# RA register map
Vendor: Renesas; Series: All Chips; File version: x.xx
Registers are 32-bit, read-write, reset 0x0 unless marked. A register's access mark holds for its fields unless they carry their own. Offsets are from the block's base; [hi:lo] are bit positions; {n}, {i} and the like mark numbered series.

## R_SPI0 — Serial Peripheral Interface
Base 0x40072000
Same registers: R_SPI1 0x40072100
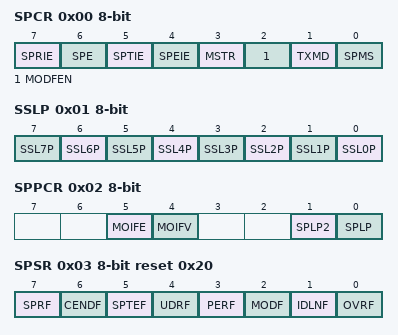
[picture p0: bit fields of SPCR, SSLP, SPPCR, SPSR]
0x00 SPCR 8-bit — SPI Control Register
  [7] SPRIE — SPI Receive Buffer Full Interrupt Enable
    0=Disables the generation of SPI receive buffer full interrupt requests; 1=Enables the generation of SPI receive buffer full interrupt requests
  [6] SPE — SPI Function Enable
    0=Disables the SPI function; 1=Enables the SPI function
  [5] SPTIE — Transmit Buffer Empty Interrupt Enable
    0=Disables the generation of transmit buffer empty interrupt requests; 1=Enables the generation of transmit buffer empty interrupt requests
  [4] SPEIE — SPI Error Interrupt Enable
    0=Disables the generation of SPI error interrupt requests; 1=Enables the generation of SPI error interrupt requests
  [3] MSTR — SPI Master/Slave Mode Select
    0=Slave mode; 1=Master mode
  [2] MODFEN — Mode Fault Error Detection Enable
    0=Disables the detection of mode fault error; 1=Enables the detection of mode fault error
  [1] TXMD — Communications Operating Mode Select
    0=Full-duplex synchronous serial communications; 1=Serial communications consisting of only transmit operations
  [0] SPMS — SPI Mode Select
    0=SPI operation (4-wire method); 1=Clock synchronous operation (3-wire method)
0x01 SSLP 8-bit — SPI Slave Select Polarity Register
  [n] SSL{n}P (n=0..7) — SSL{n} Signal Polarity Setting
    0=SSL{n} signal is active low; 1=SSL{n} signal is active high
0x02 SPPCR 8-bit — SPI Pin Control Register
  [5] MOIFE — MOSI Idle Value Fixing Enable
    0=MOSI output value equals final data from previous transfer; 1=MOSI output value equals the value set in the MOIFV bit
  [4] MOIFV — MOSI Idle Fixed Value
    0=The level output on the MOSIn pin during MOSI idling corresponds to low; 1=The level output on the MOSIn pin during MOSI idling corresponds to high
  [1] SPLP2 — SPI Loopback 2
    0=Normal mode; 1=Loopback mode (data is not inverted for transmission)
  [0] SPLP — SPI Loopback
    0=Normal mode; 1=Loopback mode (data is inverted for transmission)
0x03 SPSR 8-bit reset 0x20 — SPI Status Register
  [7] SPRF write-0-clears read-modifies — SPI Receive Buffer Full Flag
    0=No valid data in SPDR; 1=Valid data found in SPDR
  [6] CENDF — Communication End Flag
    0=The RSPI is not communicating or communicating; 1=The RSPI communication completed
  [5] SPTEF write-0-clears read-modifies — SPI Transmit Buffer Empty Flag
    0=Data found in the transmit buffer; 1=No data in the transmit buffer
  [4] UDRF write-0-clears read-modifies — Underrun Error Flag(When MODF is 0, This bit is invalid.)
    0=A mode fault error occurs (MODF=1); 1=An underrun error occurs (MODF=1)
  [3] PERF write-0-clears read-modifies — Parity Error Flag
    0=No parity error occurs; 1=A parity error occurs
  [2] MODF write-0-clears read-modifies — Mode Fault Error Flag
    0=Neither mode fault error nor underrun error occurs; 1=A mode fault error or an underrun error occurs
  [1] IDLNF ro — SPI Idle Flag
    0=SPI is in the idle state; 1=SPI is in the transfer state
  [0] OVRF write-0-clears read-modifies — Overrun Error Flag
    0=No overrun error occurs; 1=An overrun error occurs
0x04 SPDR — SPI Data Register
0x04 SPDR_HA 16-bit (alternate view of SPDR) — SPI Data Register ( halfword access )
0x04 SPDR_BY 8-bit (alternate view of SPDR) — SPI Data Register ( byte access )
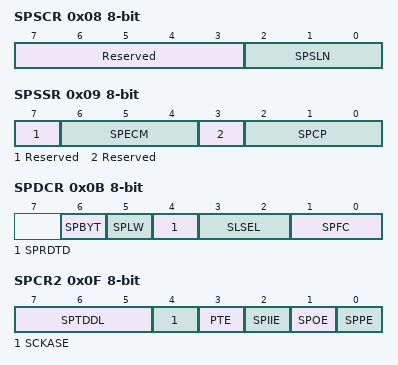
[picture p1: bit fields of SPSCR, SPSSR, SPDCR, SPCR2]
0x08 SPSCR 8-bit — SPI Sequence Control Register
  [7:3] Reserved — These bits are read as 00000. The write value should be 00000.
  [2:0] SPSLN — RSPI Sequence Length Specification The order in which the SPCMD0 to SPCMD07 registers are to be referenced is changed in accordance with the sequence length that is set in these bits. The relationship among the setting of these bits, sequence length, and SPCMD0 to SPCMD7 registers referenced by the RSPI is shown above. However, the RSPI in slave mode always references SPCMD0.
    0=Length 1 SPDMDx x = 0->0->; 1=Length 2 SPDMDx x = 0->1->0->; 2=Length 3 SPDMDx x = 0->1->2->0->; 3=Length 4 SPDMDx x = 0->1->2->3->0->; 4=Length 5 SPDMDx x = 0->1->2->3->4->0->; 5=Length 6 SPDMDx x = 0->1->2->3->4->5->0->; 6=Length 7 SPDMDx x = 0->1->2->3->4->5->6->0->; 7=Length 8 SPDMDx x = 0->1->2->3->4->5->6->7->0->
0x09 SPSSR 8-bit ro — SPI Sequence Status Register
  [7] Reserved — This bit is read as 0.
  [6:4] SPECM — RSPI Error Command
    {v}=SPCMD{v} (v=0..7)
  [3] Reserved — This bit is read as 0.
  [2:0] SPCP — RSPI Command Pointer
    {v}=SPCMD{v} (v=0..7)
0x0A SPBR 8-bit reset 0xFF — SPI Bit Rate Register
  [7:0] SPR — SPBR sets the bit rate in master mode.
0x0B SPDCR 8-bit — SPI Data Control Register
  [6] SPBYT — SPI Byte Access Specification
    0=SPDR is accessed in halfword or word (SPLW is valid); 1=SPDR is accessed in byte (SPLW is invalid)
  [5] SPLW — SPI Word Access/Halfword Access Specification
    0=Set SPDR_HA to valid for halfword access; 1=Set SPDR to valid for word access
  [4] SPRDTD — SPI Receive/Transmit Data Selection
    0=SPDR values are read from the receive buffer; 1=SPDR values are read from the transmit buffer (but only if the transmit buffer is empty)
  [3:2] SLSEL — SSL Pin Output Select
    0=SSL2 to SSL7->output, SSL1->output; 1=SSL2 to SSL7->I/O, SSL1->I/O; 2=SSL2 to SSL7->I/O, SSL1->output; 3=Setting prohibited
  [1:0] SPFC — Number of Frames Specification
    0=1 frame; 1=2 frames; 2=3 frames; 3=4 frames
0x0C SPCKD 8-bit — SPI Clock Delay Register
  [2:0] SCKDL — RSPCK Delay Setting
    {v}={v+1} RSPCK (v=0..7)
0x0D SSLND 8-bit — SPI Slave Select Negation Delay Register
  [2:0] SLNDL — SSL Negation Delay Setting
    {v}={v+1} RSPCK (v=0..7)
0x0E SPND 8-bit — SPI Next-Access Delay Register
  [2:0] SPNDL — SPI Next-Access Delay Setting
    {v}={v+1} RSPCK + 2 PCLK (v=0..7)
0x0F SPCR2 8-bit — SPI Control Register 2
  [7:5] SPTDDL — RSPI Transmit Data Delay
    {v}=Same as above (v=2..7)
  [4] SCKASE — RSPCK Auto-Stop Function Enable
    0=Disables the RSPCK auto-stop function; 1=Enables the RSPCK auto-stop function
  [3] PTE — Parity Self-Testing
    0=Disables the self-diagnosis function of the parity circuit; 1=Enables the self-diagnosis function of the parity circuit
  [2] SPIIE — SPI Idle Interrupt Enable
    0=Disables the generation of idle interrupt requests; 1=Enables the generation of idle interrupt requests
  [1] SPOE — Parity Mode
    0=Selects even parity for use in transmission and reception; 1=Selects odd parity for use in transmission and reception
  [0] SPPE — Parity Enable
    0=Does not add the parity bit to transmit data and does not check the parity bit of receive data; 1=Adds the parity bit to transmit data and checks the parity bit of receive data (when SPCR.TXMD = 0) / Adds the parity bit to transmit data but does not check the parity bit of receive data (when SPCR.TXMD = 1)
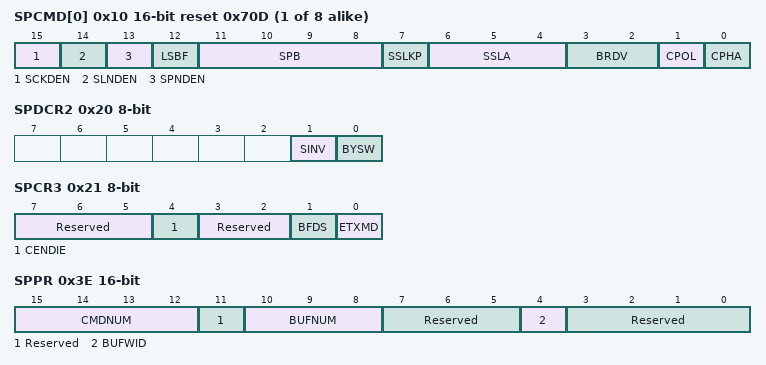
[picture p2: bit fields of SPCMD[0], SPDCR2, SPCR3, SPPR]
{0x10+2i} SPCMD[{i}] (i=0..7) 16-bit reset 0x70D — SPI Command Register {i}
  [15] SCKDEN — RSPCK Delay Setting Enable
    0=An RSPCK delay of 1 RSPCK; 1=An RSPCK delay is equal to the setting of the SPI clock delay register (SPCKD)
  [14] SLNDEN — SSL Negation Delay Setting Enable
    0=An SSL negation delay of 1 RSPCK; 1=An SSL negation delay is equal to the setting of the SPI slave select negation delay register (SSLND)
  [13] SPNDEN — SPI Next-Access Delay Enable
    0=A next-access delay of 1 RSPCK + 2 PCLK; 1=A next-access delay is equal to the setting of the SPI next-access delay register (SPND)
  [12] LSBF — SPI LSB First
    0=MSB first; 1=LSB first
  [11:8] SPB — SPI Data Length Setting
    {v}=8 bits (v=4..7); {v}={v+1} bits (v=8..15); other=others (Setting prohibited)
  [7] SSLKP — SSL Signal Level Keeping
    0=Negates all SSL signals upon completion of transfer; 1=Keeps the SSL signal level from the end of transfer until the beginning of the next access
  [6:4] SSLA — SSL Signal Assertion Setting
    {v}=SSL{v} (v=0..3); other=others (Setting prohibited)
  [3:2] BRDV — Bit Rate Division Setting
    0=These bits select the base bit rate; 1=These bits select the base bit rate divided by 2; 2=These bits select the base bit rate divided by 4; 3=These bits select the base bit rate divided by 8
  [1] CPOL — RSPCK Polarity Setting
    0=RSPCK is low when idle; 1=RSPCK is high when idle
  [0] CPHA — RSPCK Phase Setting
    0=Data sampling on odd edge, data variation on even edge; 1=Data variation on odd edge, data sampling on even edge
0x20 SPDCR2 8-bit — SPI Data Control Register 2
  [1] SINV — Serial data invert bit
    0=Not invert serial data; 1=Invert serial data
  [0] BYSW — Byte Swap Operating Mode Select
    0=Byte Swap Operating Mode disabled; 1=Byte Swap Operating Mode enabled
0x21 SPCR3 8-bit — RSPI Control Register 3
  [7:5] Reserved — These bits are read as 000. The write value should be 000.
  [4] CENDIE — RSPI Communication End Interrupt Enable
    0=Communication end interrupt request is disabled; 1=Communication end interrupt request is enabled
  [3:2] Reserved — These bits are read as 00. The write value should be 00.
  [1] BFDS — Between Burst Transfer Frames Delay Select
    0=Delay (RSPCK delay, SSL negation delay and next-access delay) between frames is inserted in burst transfer; 1=Delay between frames is not inserted in burst transfer
  [0] ETXMD — Extended Communication Mode Select
    0=Full-duplex synchronous or transmit-only serial communications; 1=Receive-only serial communications in slave mode (SPCR.MSTR bit = 0)
0x3E SPPR 16-bit — RSPI Parameter Read Register
  [15:12] CMDNUM — Command Number check
    1=1 Command; 8=8 Command
  [11] Reserved — This bit is read as 0. The write value should be 0.
  [10:8] BUFNUM — Buffer Number check
    1=1 Buffer; 4=4 Buffer
  [7:5] Reserved — These bits are read as 000. The write value should be 000.
  [4] BUFWID — Buffer Width check
    0=16bit; 1=32bit
  [3:0] Reserved — These bits are read as 0000. The write value should be 0000.
